VERSION ""

NS_ :

BS_:

BU_: JETSON VCU ACU RES DYN_F DYN_R FSG_DATA_LOGGER

BO_ 3221225472 VECTOR__INDEPENDENT_SIG_MSG: 0 Vector__XXX
 SG_ EBS_Pressure_Rear : 32|8@1+ (10,0) [0|150] "bar" Vector__XXX
 SG_ EBS_Pressure_Front : 24|8@1+ (10,0) [0|150] "bar" Vector__XXX
 SG_ NewSignal_0005 : 0|8@1+ (1,0) [0|0] "" Vector__XXX
 SG_ NewSignal_0015 : 32|8@1+ (1,0) [0|0] "" Vector__XXX
 SG_ ACU_State : 0|8@1+ (1,0) [0|0] "" Vector__XXX
 SG_ assi_state : 8|8@1+ (1,0) [0|0] "" Vector__XXX
 SG_ Internal_temperature : 16|8@1+ (1,0) [0|0] "º" Vector__XXX
 SG_ ignition_manual : 0|8@1+ (1,0) [0|0] "" Vector__XXX
 SG_ r2d_manual : 8|8@1+ (1,0) [0|0] "" Vector__XXX
 SG_ ignition_auto : 16|8@1+ (1,0) [0|0] "" Vector__XXX
 SG_ r2d_auto : 24|8@1+ (1,0) [0|0] "" Vector__XXX
 SG_ shutdown_signal : 32|8@1+ (1,0) [0|0] "" Vector__XXX
 SG_ vcu_state : 40|8@1+ (1,0) [0|0] "" Vector__XXX
 SG_ EBS_Pressure_Tank_Front : 0|8@1+ (10,0) [0|0] "bar" Vector__XXX
 SG_ EBS_Pressure_Tank_Rear : 8|8@1+ (10,0) [0|0] "bar" Vector__XXX
 SG_ Brake_Pressure_Front : 16|8@1+ (10,0) [0|0] "bar" Vector__XXX
 SG_ Brake_Pressure_Rear : 24|8@1+ (10,0) [0|0] "bar" Vector__XXX
 SG_ SPD_LEFT : 0|16@1+ (0.1,0) [0|0] "km/h" Vector__XXX
 SG_ SPD_RIGHT : 16|16@1+ (0.1,0) [0|0] "km/h" Vector__XXX
 SG_ BRK_PRESS : 0|16@1+ (0.1,0) [0|0] "bar" Vector__XXX
 SG_ SUSP_R : 16|16@1+ (0.1,0) [0|0] "mm" Vector__XXX
 SG_ SUSP_L : 32|16@1+ (0.1,0) [0|0] "mm" Vector__XXX
 SG_ SPD_LEFT : 0|16@1+ (0.1,0) [0|0] "km/h" Vector__XXX
 SG_ SPD_RIGHT : 16|16@1+ (0.1,0) [0|0] "km/h" Vector__XXX
 SG_ ST_ANGLE : 0|16@1- (0.1,0) [0|0] "º" Vector__XXX
 SG_ SUSP_R : 16|16@1+ (0.1,0) [0|0] "mm" Vector__XXX
 SG_ SUSP_L : 32|16@1+ (0.1,0) [0|0] "mm" Vector__XXX
 SG_ SIGNAL : 0|8@1+ (1,0) [0|0] ""  JETSON,ACU
 SG_ HV : 0|8@1+ (1,0) [0|0] ""  ACU
 SG_ Brake_pressure_Front : 8|8@1+ (1,0) [0|0] "" Vector__XXX
 SG_ Brake_pressure_Rear : 16|8@1+ (1,0) [0|0] "" Vector__XXX
 SG_ STATE : 0|8@1+ (1,0) [0|0] ""  VCU,ACU
 SG_ RD : 0|8@1+ (1,0) [0|0] ""  JETSON
 SG_ IGN : 0|8@1+ (1,0) [0|1] ""  VCU
 SG_ ASMS : 8|8@1+ (1,0) [0|1] ""  VCU
 SG_ Emergency : 16|8@1+ (1,0) [0|0] ""  VCU
 SG_ Speed_actual : 0|8@1+ (0.5,0) [0|0] "Km/h"  VCU
 SG_ Speed_target : 8|8@1+ (0.5,0) [0|0] "Km/h" Vector__XXX
 SG_ Steering_angle_actual : 16|8@1- (0.5,0) [0|0] "º" Vector__XXX
 SG_ Steering_angle_target : 24|8@1- (0.5,0) [0|0] "º" Vector__XXX
 SG_ RPM : 0|16@1- (1,0) [0|6000] "RPM"  JETSON
 SG_ Mission_Select : 0|8@1+ (1,0) [0|0] ""  ACU
 SG_ Mission_Select : 0|8@1+ (1,0) [0|0] ""  JETSON

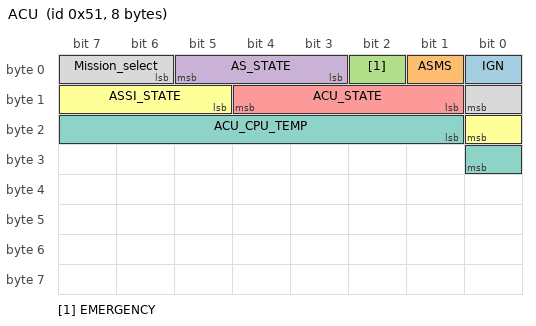
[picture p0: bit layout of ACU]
BO_ 81 ACU: 8 ACU
 SG_ IGN : 0|1@1+ (1,0) [0|1] "" Vector__XXX
 SG_ ASMS : 1|1@1+ (1,0) [0|1] "" Vector__XXX
 SG_ EMERGENCY : 2|1@1+ (1,0) [0|1] "" Vector__XXX
 SG_ AS_STATE : 3|3@1+ (1,0) [0|0] "" Vector__XXX
 SG_ ACU_STATE : 9|4@1+ (1,0) [0|0] "" Vector__XXX
 SG_ ASSI_STATE : 13|4@1+ (1,0) [0|0] "" Vector__XXX
 SG_ ACU_CPU_TEMP : 17|8@1+ (1,0) [0|255] "º" Vector__XXX
 SG_ Mission_select : 6|3@1+ (1,0) [0|0] "" Vector__XXX

CM_ SG_ 3221225472 EBS_Pressure_Rear "(null)";
CM_ SG_ 3221225472 EBS_Pressure_Front "Perdu gay";
CM_ SG_ 3221225472 STATE "Regulations";
VAL_ 81 IGN 0 "OFF" 1 "ON" ;
VAL_ 81 ASMS 0 "OFF" 1 "ON" ;
VAL_ 81 EMERGENCY 0 "OFF" 1 "ON" ;
VAL_ 81 AS_STATE 1 "OFF" 2 "READY" 3 "DRIVING" 4 "EMERGENCY" 5 "FINISH" ;
VAL_ 81 ACU_STATE 0 "INIT" 1 "MISSION_SELECT" 2 "JETSON_WAITING" 3 "INIT_SEQUENCE" 4 "READY" 5 "DRIVING" 6 "EBS_ERROR" 7 "EMERGENCY" 8 "FINISHED" 9 "MANUAL" ;
VAL_ 81 ASSI_STATE 1 "OFF" 2 "READY" 3 "DRIVING" 4 "EMERGENCY" 5 "FINISH" ;
